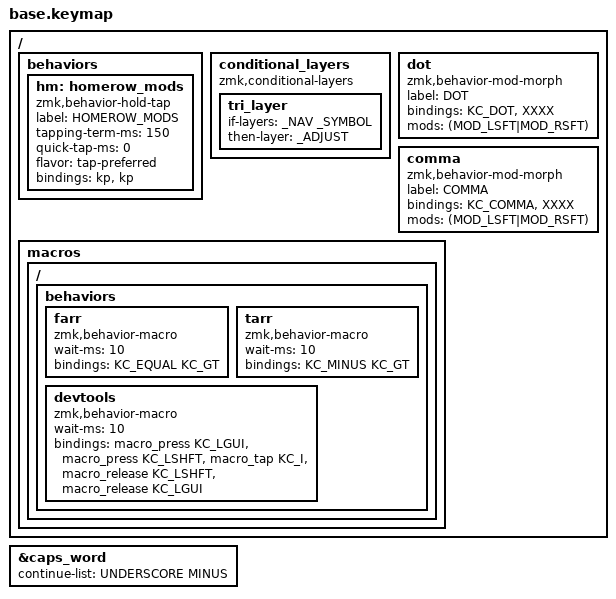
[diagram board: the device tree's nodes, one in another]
#include <behaviors.dtsi>
#include "keycodes.h"

/* DEFAULT LAYER */
#define DTR       KC_Q     KC_W     KC_E     KC_R     KC_T        KC_Y     KC_U     KC_I     KC_O     KC_P    
#define DMR       GUI_A    ALT_S    CTRL_D   SHFT_F   KC_G        KC_H     SHFT_J   CTRL_K   ALT_L    GUI_SEMI
#define DBR(L, R) MEH_Z    KC_X     KC_C     KC_V     KC_B L    R KC_N     KC_M     &comma   &dot     MEH_FSLH 
#define DTHR                        KC_BSPC  NAV  KC_SPACE        KC_RET   SYM_TAB  KC_ESC


/* NUMBER/NAV LAYER */
#define NTR       KC_N1    KC_N2    KC_N3    KC_N4    KC_N5       KC_N6    KC_N7    KC_N8    KC_N9    KC_N0   
#define NMR       KC_LGUI  KC_RALT  KC_LCTRL KC_LSHFT XXXX        KC_LEFT  KC_DOWN  KC_UP    KC_RIGHT XXXX    
#define NBR(L, R) ____     XXXX    &devtools XXXX     XXXX L    R XXXX     CAPSWRD   XXXX    XXXX     ____    
#define NTHR                        KC_DEL   ____     ____        ____     ____     ____


/* SYMBOL LAYER */
#define STR       KC_EXCL  KC_AT    KC_HASH  KC_DLLR  KC_PRCNT    KC_CARET KC_AMPS  KC_STAR  XXXX     KC_BSLH 
#define SMR       KC_SQT   KC_LT    KC_LBKT  KC_LPAR  KC_LBRC     &farr    KC_EQUAL KC_MINUS KC_GRAVE KC_PIPE 
#define SBR(L, R) KC_DQT   KC_GT    KC_RBKT  KC_RPAR  KC_RBRC L R &tarr    KC_PLUS  XXXX     KC_TILDE XXXX    
#define STHR                        ____    ____      KC_UNDER    ____     ____     ____

/* ADJUST LAYER */
#define ATR       KC_F1    KC_F2    KC_F3    KC_F4    KC_F5       KC_F6    KC_F7    KC_F8    KC_F9    KC_F10  
#define AMR       BT_SEL5  BT_SEL4  BT_SEL3  BT_SEL2  BT_SEL1     XXXX     XXXX     XXXX     XXXX     KC_F11  
#define ABR(L, R) USB_BT   XXXX     XXXX     XXXX     REBOOT L  R REBOOT   BT__CLR  XXXX     XXXX     KC_F12  
#define ATHR                        ____     ____     ____        ____     ____     ____

#define COMBO(NAME, KEYPOS, LAYERS, BINDINGS) \
  combo_##NAME { \
    bindings = <BINDINGS>; \
    key-positions = KEYPOS; \
    layers = <LAYERS>; \
  };

&caps_word {
  continue-list = <UNDERSCORE MINUS>;
};

/ {
  behaviors {
    hm: homerow_mods {
      compatible = "zmk,behavior-hold-tap";
      label = "HOMEROW_MODS";
      #binding-cells = <2>;
      tapping-term-ms = <150>;
      quick-tap-ms = <0>;
      flavor = "tap-preferred";
      bindings = <&kp>, <&kp>;
    };
  };
    
  conditional_layers {
    compatible = "zmk,conditional-layers";
    tri_layer {
      if-layers = <_NAV _SYMBOL>;
      then-layer = <_ADJUST>;
    };
  };

  dot: dot {
    compatible = "zmk,behavior-mod-morph";
    label = "DOT";
    #binding-cells = <0>;
    bindings = <KC_DOT>, <XXXX>;
    mods = <(MOD_LSFT|MOD_RSFT)>;
  };

  comma: comma {
    compatible = "zmk,behavior-mod-morph";
    label = "COMMA";
    #binding-cells = <0>;
    bindings = <KC_COMMA>, <XXXX>;
    mods = <(MOD_LSFT|MOD_RSFT)>;
  };
  
  macros {
    ZMK_MACRO(farr,
      wait-ms = <10>;
      bindings = <KC_EQUAL KC_GT>;
    )
    ZMK_MACRO(tarr,
      wait-ms = <10>;
      bindings = <KC_MINUS KC_GT>;
    )
    ZMK_MACRO(devtools,
      wait-ms = <10>;
      bindings
          = <&macro_press KC_LGUI>
          , <&macro_press KC_LSHFT>
          , <&macro_tap KC_I>
          , <&macro_release KC_LSHFT>
          , <&macro_release KC_LGUI>;
    )
  };
};
